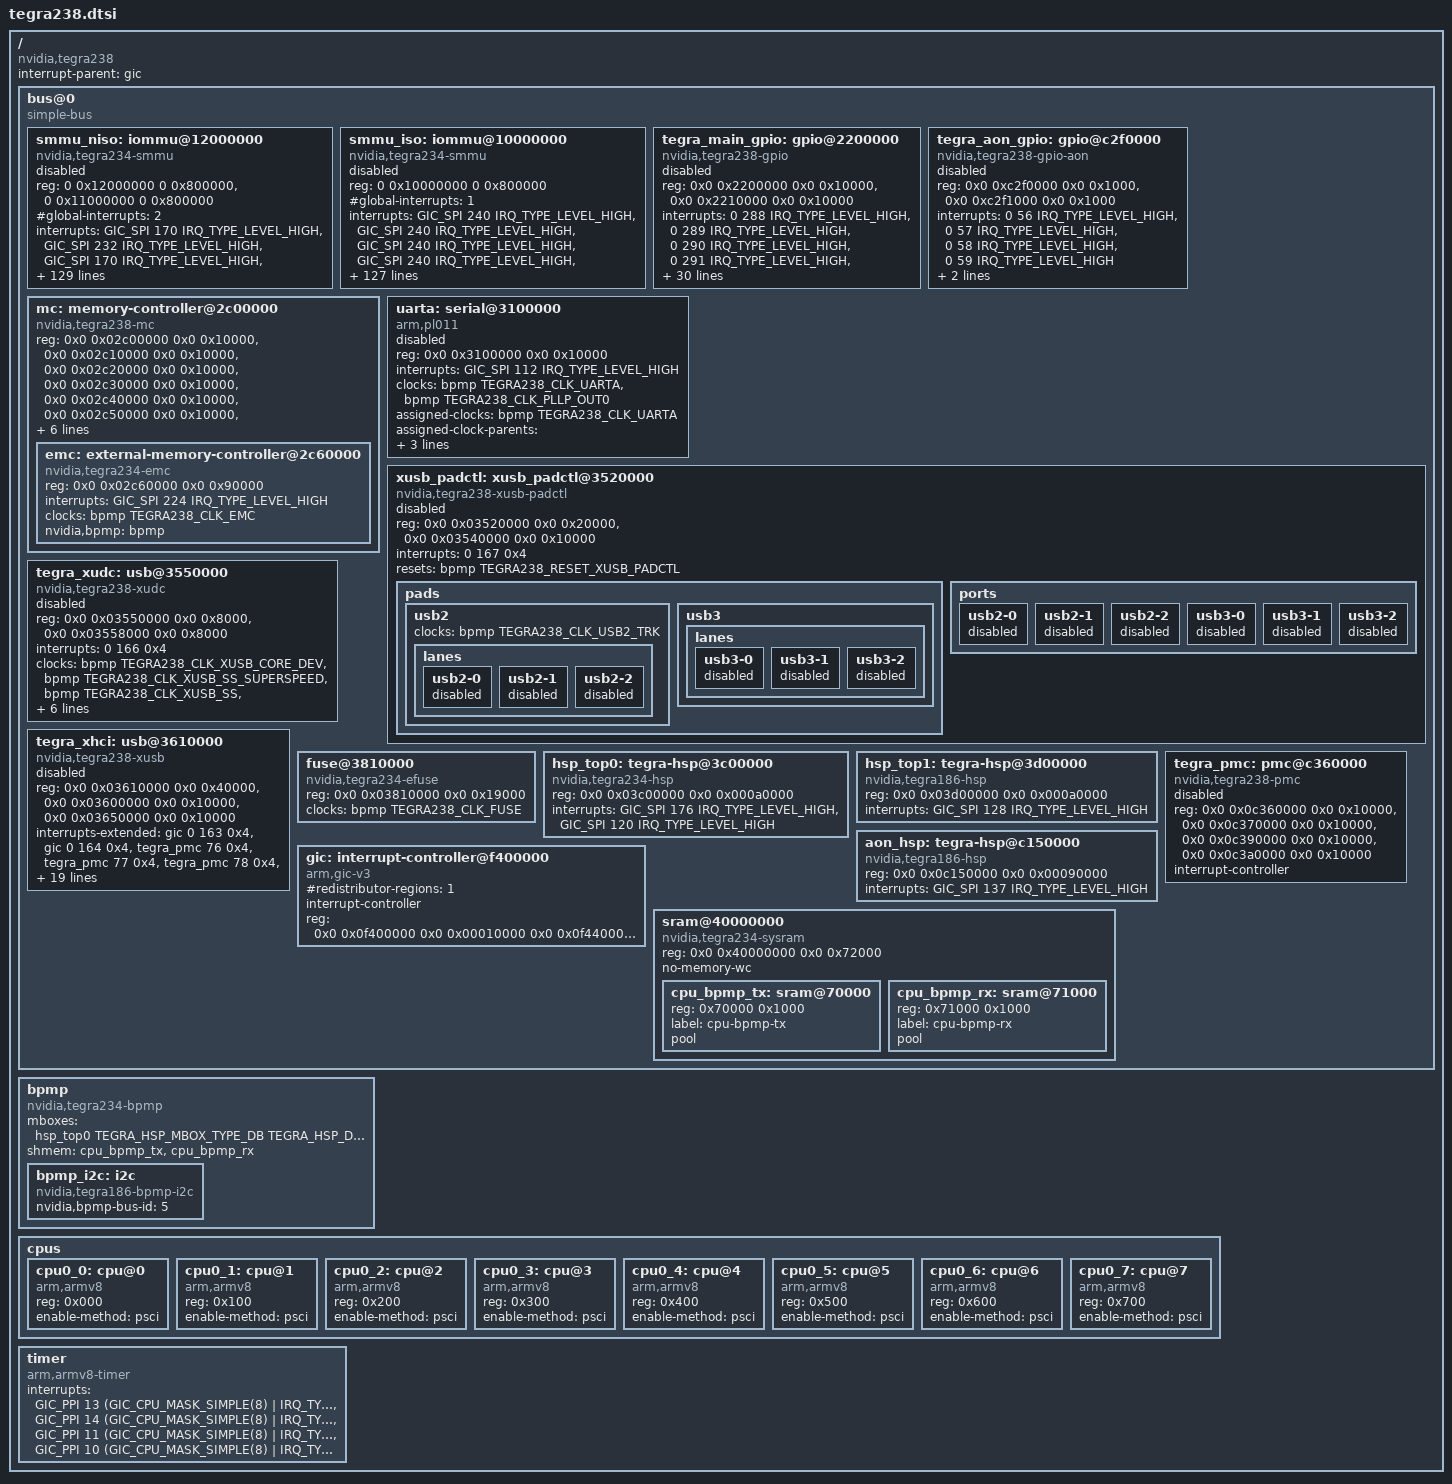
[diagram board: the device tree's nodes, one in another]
/* SPDX-License-Identifier: (GPL-2.0-only OR BSD-2-Clause) */

#include <dt-bindings/clock/nvidia,tegra238.h>
#include <dt-bindings/interrupt-controller/arm-gic.h>
#include <dt-bindings/mailbox/tegra186-hsp.h>
#include <dt-bindings/reset/nvidia,tegra238.h>
#include <dt-bindings/memory/nvidia,tegra238-mc.h>

/ {
	compatible = "nvidia,tegra238";
	interrupt-parent = <&gic>;
	#address-cells = <2>;
	#size-cells = <2>;

	bus@0 {
		compatible = "simple-bus";

		#address-cells = <2>;
		#size-cells = <2>;
		ranges = <0x0 0x0 0x0 0x0 0x0 0x80000000>;

		smmu_niso: iommu@12000000{
			compatible = "nvidia,tegra234-smmu", "nvidia,smmu-500";
			reg = <0 0x12000000 0 0x800000>,
			      <0 0x11000000 0 0x800000>;
			#global-interrupts = <2>;
			interrupts = <GIC_SPI 170 IRQ_TYPE_LEVEL_HIGH>,
				     <GIC_SPI 232 IRQ_TYPE_LEVEL_HIGH>,
				     <GIC_SPI 170 IRQ_TYPE_LEVEL_HIGH>,
				     <GIC_SPI 232 IRQ_TYPE_LEVEL_HIGH>,
				     <GIC_SPI 170 IRQ_TYPE_LEVEL_HIGH>,
				     <GIC_SPI 170 IRQ_TYPE_LEVEL_HIGH>,
				     <GIC_SPI 170 IRQ_TYPE_LEVEL_HIGH>,
				     <GIC_SPI 170 IRQ_TYPE_LEVEL_HIGH>,
				     <GIC_SPI 170 IRQ_TYPE_LEVEL_HIGH>,
				     <GIC_SPI 170 IRQ_TYPE_LEVEL_HIGH>,
				     <GIC_SPI 170 IRQ_TYPE_LEVEL_HIGH>,
				     <GIC_SPI 170 IRQ_TYPE_LEVEL_HIGH>,
				     <GIC_SPI 170 IRQ_TYPE_LEVEL_HIGH>,
				     <GIC_SPI 170 IRQ_TYPE_LEVEL_HIGH>,
				     <GIC_SPI 170 IRQ_TYPE_LEVEL_HIGH>,
				     <GIC_SPI 170 IRQ_TYPE_LEVEL_HIGH>,
				     <GIC_SPI 170 IRQ_TYPE_LEVEL_HIGH>,
				     <GIC_SPI 170 IRQ_TYPE_LEVEL_HIGH>,
				     <GIC_SPI 170 IRQ_TYPE_LEVEL_HIGH>,
				     <GIC_SPI 170 IRQ_TYPE_LEVEL_HIGH>,
				     <GIC_SPI 170 IRQ_TYPE_LEVEL_HIGH>,
				     <GIC_SPI 170 IRQ_TYPE_LEVEL_HIGH>,
				     <GIC_SPI 170 IRQ_TYPE_LEVEL_HIGH>,
				     <GIC_SPI 170 IRQ_TYPE_LEVEL_HIGH>,
				     <GIC_SPI 170 IRQ_TYPE_LEVEL_HIGH>,
				     <GIC_SPI 170 IRQ_TYPE_LEVEL_HIGH>,
				     <GIC_SPI 170 IRQ_TYPE_LEVEL_HIGH>,
				     <GIC_SPI 170 IRQ_TYPE_LEVEL_HIGH>,
				     <GIC_SPI 170 IRQ_TYPE_LEVEL_HIGH>,
				     <GIC_SPI 170 IRQ_TYPE_LEVEL_HIGH>,
				     <GIC_SPI 170 IRQ_TYPE_LEVEL_HIGH>,
				     <GIC_SPI 170 IRQ_TYPE_LEVEL_HIGH>,
				     <GIC_SPI 170 IRQ_TYPE_LEVEL_HIGH>,
				     <GIC_SPI 170 IRQ_TYPE_LEVEL_HIGH>,
				     <GIC_SPI 170 IRQ_TYPE_LEVEL_HIGH>,
				     <GIC_SPI 170 IRQ_TYPE_LEVEL_HIGH>,
				     <GIC_SPI 170 IRQ_TYPE_LEVEL_HIGH>,
				     <GIC_SPI 170 IRQ_TYPE_LEVEL_HIGH>,
				     <GIC_SPI 170 IRQ_TYPE_LEVEL_HIGH>,
				     <GIC_SPI 170 IRQ_TYPE_LEVEL_HIGH>,
				     <GIC_SPI 170 IRQ_TYPE_LEVEL_HIGH>,
				     <GIC_SPI 170 IRQ_TYPE_LEVEL_HIGH>,
				     <GIC_SPI 170 IRQ_TYPE_LEVEL_HIGH>,
				     <GIC_SPI 170 IRQ_TYPE_LEVEL_HIGH>,
				     <GIC_SPI 170 IRQ_TYPE_LEVEL_HIGH>,
				     <GIC_SPI 170 IRQ_TYPE_LEVEL_HIGH>,
				     <GIC_SPI 170 IRQ_TYPE_LEVEL_HIGH>,
				     <GIC_SPI 170 IRQ_TYPE_LEVEL_HIGH>,
				     <GIC_SPI 170 IRQ_TYPE_LEVEL_HIGH>,
				     <GIC_SPI 170 IRQ_TYPE_LEVEL_HIGH>,
				     <GIC_SPI 170 IRQ_TYPE_LEVEL_HIGH>,
				     <GIC_SPI 170 IRQ_TYPE_LEVEL_HIGH>,
				     <GIC_SPI 170 IRQ_TYPE_LEVEL_HIGH>,
				     <GIC_SPI 170 IRQ_TYPE_LEVEL_HIGH>,
				     <GIC_SPI 170 IRQ_TYPE_LEVEL_HIGH>,
				     <GIC_SPI 170 IRQ_TYPE_LEVEL_HIGH>,
				     <GIC_SPI 170 IRQ_TYPE_LEVEL_HIGH>,
				     <GIC_SPI 170 IRQ_TYPE_LEVEL_HIGH>,
				     <GIC_SPI 170 IRQ_TYPE_LEVEL_HIGH>,
				     <GIC_SPI 170 IRQ_TYPE_LEVEL_HIGH>,
				     <GIC_SPI 170 IRQ_TYPE_LEVEL_HIGH>,
				     <GIC_SPI 170 IRQ_TYPE_LEVEL_HIGH>,
				     <GIC_SPI 170 IRQ_TYPE_LEVEL_HIGH>,
				     <GIC_SPI 170 IRQ_TYPE_LEVEL_HIGH>,
				     <GIC_SPI 170 IRQ_TYPE_LEVEL_HIGH>,
				     <GIC_SPI 170 IRQ_TYPE_LEVEL_HIGH>,
				     <GIC_SPI 170 IRQ_TYPE_LEVEL_HIGH>,
				     <GIC_SPI 170 IRQ_TYPE_LEVEL_HIGH>,
				     <GIC_SPI 170 IRQ_TYPE_LEVEL_HIGH>,
				     <GIC_SPI 170 IRQ_TYPE_LEVEL_HIGH>,
				     <GIC_SPI 170 IRQ_TYPE_LEVEL_HIGH>,
				     <GIC_SPI 170 IRQ_TYPE_LEVEL_HIGH>,
				     <GIC_SPI 170 IRQ_TYPE_LEVEL_HIGH>,
				     <GIC_SPI 170 IRQ_TYPE_LEVEL_HIGH>,
				     <GIC_SPI 170 IRQ_TYPE_LEVEL_HIGH>,
				     <GIC_SPI 170 IRQ_TYPE_LEVEL_HIGH>,
				     <GIC_SPI 170 IRQ_TYPE_LEVEL_HIGH>,
				     <GIC_SPI 170 IRQ_TYPE_LEVEL_HIGH>,
				     <GIC_SPI 170 IRQ_TYPE_LEVEL_HIGH>,
				     <GIC_SPI 170 IRQ_TYPE_LEVEL_HIGH>,
				     <GIC_SPI 170 IRQ_TYPE_LEVEL_HIGH>,
				     <GIC_SPI 170 IRQ_TYPE_LEVEL_HIGH>,
				     <GIC_SPI 170 IRQ_TYPE_LEVEL_HIGH>,
				     <GIC_SPI 170 IRQ_TYPE_LEVEL_HIGH>,
				     <GIC_SPI 170 IRQ_TYPE_LEVEL_HIGH>,
				     <GIC_SPI 170 IRQ_TYPE_LEVEL_HIGH>,
				     <GIC_SPI 170 IRQ_TYPE_LEVEL_HIGH>,
				     <GIC_SPI 170 IRQ_TYPE_LEVEL_HIGH>,
				     <GIC_SPI 170 IRQ_TYPE_LEVEL_HIGH>,
				     <GIC_SPI 170 IRQ_TYPE_LEVEL_HIGH>,
				     <GIC_SPI 170 IRQ_TYPE_LEVEL_HIGH>,
				     <GIC_SPI 170 IRQ_TYPE_LEVEL_HIGH>,
				     <GIC_SPI 170 IRQ_TYPE_LEVEL_HIGH>,
				     <GIC_SPI 170 IRQ_TYPE_LEVEL_HIGH>,
				     <GIC_SPI 170 IRQ_TYPE_LEVEL_HIGH>,
				     <GIC_SPI 170 IRQ_TYPE_LEVEL_HIGH>,
				     <GIC_SPI 170 IRQ_TYPE_LEVEL_HIGH>,
				     <GIC_SPI 170 IRQ_TYPE_LEVEL_HIGH>,
				     <GIC_SPI 170 IRQ_TYPE_LEVEL_HIGH>,
				     <GIC_SPI 170 IRQ_TYPE_LEVEL_HIGH>,
				     <GIC_SPI 170 IRQ_TYPE_LEVEL_HIGH>,
				     <GIC_SPI 170 IRQ_TYPE_LEVEL_HIGH>,
				     <GIC_SPI 170 IRQ_TYPE_LEVEL_HIGH>,
				     <GIC_SPI 170 IRQ_TYPE_LEVEL_HIGH>,
				     <GIC_SPI 170 IRQ_TYPE_LEVEL_HIGH>,
				     <GIC_SPI 170 IRQ_TYPE_LEVEL_HIGH>,
				     <GIC_SPI 170 IRQ_TYPE_LEVEL_HIGH>,
				     <GIC_SPI 170 IRQ_TYPE_LEVEL_HIGH>,
				     <GIC_SPI 170 IRQ_TYPE_LEVEL_HIGH>,
				     <GIC_SPI 170 IRQ_TYPE_LEVEL_HIGH>,
				     <GIC_SPI 170 IRQ_TYPE_LEVEL_HIGH>,
				     <GIC_SPI 170 IRQ_TYPE_LEVEL_HIGH>,
				     <GIC_SPI 170 IRQ_TYPE_LEVEL_HIGH>,
				     <GIC_SPI 170 IRQ_TYPE_LEVEL_HIGH>,
				     <GIC_SPI 170 IRQ_TYPE_LEVEL_HIGH>,
				     <GIC_SPI 170 IRQ_TYPE_LEVEL_HIGH>,
				     <GIC_SPI 170 IRQ_TYPE_LEVEL_HIGH>,
				     <GIC_SPI 170 IRQ_TYPE_LEVEL_HIGH>,
				     <GIC_SPI 170 IRQ_TYPE_LEVEL_HIGH>,
				     <GIC_SPI 170 IRQ_TYPE_LEVEL_HIGH>,
				     <GIC_SPI 170 IRQ_TYPE_LEVEL_HIGH>,
				     <GIC_SPI 170 IRQ_TYPE_LEVEL_HIGH>,
				     <GIC_SPI 170 IRQ_TYPE_LEVEL_HIGH>,
				     <GIC_SPI 170 IRQ_TYPE_LEVEL_HIGH>,
				     <GIC_SPI 170 IRQ_TYPE_LEVEL_HIGH>,
				     <GIC_SPI 170 IRQ_TYPE_LEVEL_HIGH>,
				     <GIC_SPI 170 IRQ_TYPE_LEVEL_HIGH>,
				     <GIC_SPI 170 IRQ_TYPE_LEVEL_HIGH>,
				     <GIC_SPI 170 IRQ_TYPE_LEVEL_HIGH>,
				     <GIC_SPI 170 IRQ_TYPE_LEVEL_HIGH>;
			stream-match-mask = <0x7F80>;
			nvidia,memory-controller = <&mc>;
			#iommu-cells = <1>;
			status = "disabled";
		};

		smmu_iso: iommu@10000000{
			compatible = "nvidia,tegra234-smmu", "nvidia,smmu-500";
			reg = <0 0x10000000 0 0x800000>;
			#global-interrupts = <1>;
			interrupts = <GIC_SPI 240 IRQ_TYPE_LEVEL_HIGH>,
				     <GIC_SPI 240 IRQ_TYPE_LEVEL_HIGH>,
				     <GIC_SPI 240 IRQ_TYPE_LEVEL_HIGH>,
				     <GIC_SPI 240 IRQ_TYPE_LEVEL_HIGH>,
				     <GIC_SPI 240 IRQ_TYPE_LEVEL_HIGH>,
				     <GIC_SPI 240 IRQ_TYPE_LEVEL_HIGH>,
				     <GIC_SPI 240 IRQ_TYPE_LEVEL_HIGH>,
				     <GIC_SPI 240 IRQ_TYPE_LEVEL_HIGH>,
				     <GIC_SPI 240 IRQ_TYPE_LEVEL_HIGH>,
				     <GIC_SPI 240 IRQ_TYPE_LEVEL_HIGH>,
				     <GIC_SPI 240 IRQ_TYPE_LEVEL_HIGH>,
				     <GIC_SPI 240 IRQ_TYPE_LEVEL_HIGH>,
				     <GIC_SPI 240 IRQ_TYPE_LEVEL_HIGH>,
				     <GIC_SPI 240 IRQ_TYPE_LEVEL_HIGH>,
				     <GIC_SPI 240 IRQ_TYPE_LEVEL_HIGH>,
				     <GIC_SPI 240 IRQ_TYPE_LEVEL_HIGH>,
				     <GIC_SPI 240 IRQ_TYPE_LEVEL_HIGH>,
				     <GIC_SPI 240 IRQ_TYPE_LEVEL_HIGH>,
				     <GIC_SPI 240 IRQ_TYPE_LEVEL_HIGH>,
				     <GIC_SPI 240 IRQ_TYPE_LEVEL_HIGH>,
				     <GIC_SPI 240 IRQ_TYPE_LEVEL_HIGH>,
				     <GIC_SPI 240 IRQ_TYPE_LEVEL_HIGH>,
				     <GIC_SPI 240 IRQ_TYPE_LEVEL_HIGH>,
				     <GIC_SPI 240 IRQ_TYPE_LEVEL_HIGH>,
				     <GIC_SPI 240 IRQ_TYPE_LEVEL_HIGH>,
				     <GIC_SPI 240 IRQ_TYPE_LEVEL_HIGH>,
				     <GIC_SPI 240 IRQ_TYPE_LEVEL_HIGH>,
				     <GIC_SPI 240 IRQ_TYPE_LEVEL_HIGH>,
				     <GIC_SPI 240 IRQ_TYPE_LEVEL_HIGH>,
				     <GIC_SPI 240 IRQ_TYPE_LEVEL_HIGH>,
				     <GIC_SPI 240 IRQ_TYPE_LEVEL_HIGH>,
				     <GIC_SPI 240 IRQ_TYPE_LEVEL_HIGH>,
				     <GIC_SPI 240 IRQ_TYPE_LEVEL_HIGH>,
				     <GIC_SPI 240 IRQ_TYPE_LEVEL_HIGH>,
				     <GIC_SPI 240 IRQ_TYPE_LEVEL_HIGH>,
				     <GIC_SPI 240 IRQ_TYPE_LEVEL_HIGH>,
				     <GIC_SPI 240 IRQ_TYPE_LEVEL_HIGH>,
				     <GIC_SPI 240 IRQ_TYPE_LEVEL_HIGH>,
				     <GIC_SPI 240 IRQ_TYPE_LEVEL_HIGH>,
				     <GIC_SPI 240 IRQ_TYPE_LEVEL_HIGH>,
				     <GIC_SPI 240 IRQ_TYPE_LEVEL_HIGH>,
				     <GIC_SPI 240 IRQ_TYPE_LEVEL_HIGH>,
				     <GIC_SPI 240 IRQ_TYPE_LEVEL_HIGH>,
				     <GIC_SPI 240 IRQ_TYPE_LEVEL_HIGH>,
				     <GIC_SPI 240 IRQ_TYPE_LEVEL_HIGH>,
				     <GIC_SPI 240 IRQ_TYPE_LEVEL_HIGH>,
				     <GIC_SPI 240 IRQ_TYPE_LEVEL_HIGH>,
				     <GIC_SPI 240 IRQ_TYPE_LEVEL_HIGH>,
				     <GIC_SPI 240 IRQ_TYPE_LEVEL_HIGH>,
				     <GIC_SPI 240 IRQ_TYPE_LEVEL_HIGH>,
				     <GIC_SPI 240 IRQ_TYPE_LEVEL_HIGH>,
				     <GIC_SPI 240 IRQ_TYPE_LEVEL_HIGH>,
				     <GIC_SPI 240 IRQ_TYPE_LEVEL_HIGH>,
				     <GIC_SPI 240 IRQ_TYPE_LEVEL_HIGH>,
				     <GIC_SPI 240 IRQ_TYPE_LEVEL_HIGH>,
				     <GIC_SPI 240 IRQ_TYPE_LEVEL_HIGH>,
				     <GIC_SPI 240 IRQ_TYPE_LEVEL_HIGH>,
				     <GIC_SPI 240 IRQ_TYPE_LEVEL_HIGH>,
				     <GIC_SPI 240 IRQ_TYPE_LEVEL_HIGH>,
				     <GIC_SPI 240 IRQ_TYPE_LEVEL_HIGH>,
				     <GIC_SPI 240 IRQ_TYPE_LEVEL_HIGH>,
				     <GIC_SPI 240 IRQ_TYPE_LEVEL_HIGH>,
				     <GIC_SPI 240 IRQ_TYPE_LEVEL_HIGH>,
				     <GIC_SPI 240 IRQ_TYPE_LEVEL_HIGH>,
				     <GIC_SPI 240 IRQ_TYPE_LEVEL_HIGH>,
				     <GIC_SPI 240 IRQ_TYPE_LEVEL_HIGH>,
				     <GIC_SPI 240 IRQ_TYPE_LEVEL_HIGH>,
				     <GIC_SPI 240 IRQ_TYPE_LEVEL_HIGH>,
				     <GIC_SPI 240 IRQ_TYPE_LEVEL_HIGH>,
				     <GIC_SPI 240 IRQ_TYPE_LEVEL_HIGH>,
				     <GIC_SPI 240 IRQ_TYPE_LEVEL_HIGH>,
				     <GIC_SPI 240 IRQ_TYPE_LEVEL_HIGH>,
				     <GIC_SPI 240 IRQ_TYPE_LEVEL_HIGH>,
				     <GIC_SPI 240 IRQ_TYPE_LEVEL_HIGH>,
				     <GIC_SPI 240 IRQ_TYPE_LEVEL_HIGH>,
				     <GIC_SPI 240 IRQ_TYPE_LEVEL_HIGH>,
				     <GIC_SPI 240 IRQ_TYPE_LEVEL_HIGH>,
				     <GIC_SPI 240 IRQ_TYPE_LEVEL_HIGH>,
				     <GIC_SPI 240 IRQ_TYPE_LEVEL_HIGH>,
				     <GIC_SPI 240 IRQ_TYPE_LEVEL_HIGH>,
				     <GIC_SPI 240 IRQ_TYPE_LEVEL_HIGH>,
				     <GIC_SPI 240 IRQ_TYPE_LEVEL_HIGH>,
				     <GIC_SPI 240 IRQ_TYPE_LEVEL_HIGH>,
				     <GIC_SPI 240 IRQ_TYPE_LEVEL_HIGH>,
				     <GIC_SPI 240 IRQ_TYPE_LEVEL_HIGH>,
				     <GIC_SPI 240 IRQ_TYPE_LEVEL_HIGH>,
				     <GIC_SPI 240 IRQ_TYPE_LEVEL_HIGH>,
				     <GIC_SPI 240 IRQ_TYPE_LEVEL_HIGH>,
				     <GIC_SPI 240 IRQ_TYPE_LEVEL_HIGH>,
				     <GIC_SPI 240 IRQ_TYPE_LEVEL_HIGH>,
				     <GIC_SPI 240 IRQ_TYPE_LEVEL_HIGH>,
				     <GIC_SPI 240 IRQ_TYPE_LEVEL_HIGH>,
				     <GIC_SPI 240 IRQ_TYPE_LEVEL_HIGH>,
				     <GIC_SPI 240 IRQ_TYPE_LEVEL_HIGH>,
				     <GIC_SPI 240 IRQ_TYPE_LEVEL_HIGH>,
				     <GIC_SPI 240 IRQ_TYPE_LEVEL_HIGH>,
				     <GIC_SPI 240 IRQ_TYPE_LEVEL_HIGH>,
				     <GIC_SPI 240 IRQ_TYPE_LEVEL_HIGH>,
				     <GIC_SPI 240 IRQ_TYPE_LEVEL_HIGH>,
				     <GIC_SPI 240 IRQ_TYPE_LEVEL_HIGH>,
				     <GIC_SPI 240 IRQ_TYPE_LEVEL_HIGH>,
				     <GIC_SPI 240 IRQ_TYPE_LEVEL_HIGH>,
				     <GIC_SPI 240 IRQ_TYPE_LEVEL_HIGH>,
				     <GIC_SPI 240 IRQ_TYPE_LEVEL_HIGH>,
				     <GIC_SPI 240 IRQ_TYPE_LEVEL_HIGH>,
				     <GIC_SPI 240 IRQ_TYPE_LEVEL_HIGH>,
				     <GIC_SPI 240 IRQ_TYPE_LEVEL_HIGH>,
				     <GIC_SPI 240 IRQ_TYPE_LEVEL_HIGH>,
				     <GIC_SPI 240 IRQ_TYPE_LEVEL_HIGH>,
				     <GIC_SPI 240 IRQ_TYPE_LEVEL_HIGH>,
				     <GIC_SPI 240 IRQ_TYPE_LEVEL_HIGH>,
				     <GIC_SPI 240 IRQ_TYPE_LEVEL_HIGH>,
				     <GIC_SPI 240 IRQ_TYPE_LEVEL_HIGH>,
				     <GIC_SPI 240 IRQ_TYPE_LEVEL_HIGH>,
				     <GIC_SPI 240 IRQ_TYPE_LEVEL_HIGH>,
				     <GIC_SPI 240 IRQ_TYPE_LEVEL_HIGH>,
				     <GIC_SPI 240 IRQ_TYPE_LEVEL_HIGH>,
				     <GIC_SPI 240 IRQ_TYPE_LEVEL_HIGH>,
				     <GIC_SPI 240 IRQ_TYPE_LEVEL_HIGH>,
				     <GIC_SPI 240 IRQ_TYPE_LEVEL_HIGH>,
				     <GIC_SPI 240 IRQ_TYPE_LEVEL_HIGH>,
				     <GIC_SPI 240 IRQ_TYPE_LEVEL_HIGH>,
				     <GIC_SPI 240 IRQ_TYPE_LEVEL_HIGH>,
				     <GIC_SPI 240 IRQ_TYPE_LEVEL_HIGH>,
				     <GIC_SPI 240 IRQ_TYPE_LEVEL_HIGH>,
				     <GIC_SPI 240 IRQ_TYPE_LEVEL_HIGH>,
				     <GIC_SPI 240 IRQ_TYPE_LEVEL_HIGH>,
				     <GIC_SPI 240 IRQ_TYPE_LEVEL_HIGH>,
				     <GIC_SPI 240 IRQ_TYPE_LEVEL_HIGH>;
			stream-match-mask = <0x7F80>;
			nvidia,memory-controller = <&mc>;
			#iommu-cells = <1>;
			status = "disabled";
		};

		tegra_main_gpio: gpio@2200000 {
			compatible = "nvidia,tegra238-gpio";
			reg-names = "security", "gpio";
			reg =
				<0x0 0x2200000 0x0 0x10000>,
				<0x0 0x2210000 0x0 0x10000>;
			interrupts =
				<0 288 IRQ_TYPE_LEVEL_HIGH>,
				<0 289 IRQ_TYPE_LEVEL_HIGH>,
				<0 290 IRQ_TYPE_LEVEL_HIGH>,
				<0 291 IRQ_TYPE_LEVEL_HIGH>,
				<0 292 IRQ_TYPE_LEVEL_HIGH>,
				<0 293 IRQ_TYPE_LEVEL_HIGH>,
				<0 294 IRQ_TYPE_LEVEL_HIGH>,
				<0 295 IRQ_TYPE_LEVEL_HIGH>,
				<0 296 IRQ_TYPE_LEVEL_HIGH>,
				<0 297 IRQ_TYPE_LEVEL_HIGH>,
				<0 298 IRQ_TYPE_LEVEL_HIGH>,
				<0 299 IRQ_TYPE_LEVEL_HIGH>,
				<0 300 IRQ_TYPE_LEVEL_HIGH>,
				<0 301 IRQ_TYPE_LEVEL_HIGH>,
				<0 302 IRQ_TYPE_LEVEL_HIGH>,
				<0 303 IRQ_TYPE_LEVEL_HIGH>,
				<0 304 IRQ_TYPE_LEVEL_HIGH>,
				<0 305 IRQ_TYPE_LEVEL_HIGH>,
				<0 306 IRQ_TYPE_LEVEL_HIGH>,
				<0 307 IRQ_TYPE_LEVEL_HIGH>,
				<0 308 IRQ_TYPE_LEVEL_HIGH>,
				<0 309 IRQ_TYPE_LEVEL_HIGH>,
				<0 310 IRQ_TYPE_LEVEL_HIGH>,
				<0 311 IRQ_TYPE_LEVEL_HIGH>,
				<0 312 IRQ_TYPE_LEVEL_HIGH>,
				<0 313 IRQ_TYPE_LEVEL_HIGH>,
				<0 314 IRQ_TYPE_LEVEL_HIGH>,
				<0 315 IRQ_TYPE_LEVEL_HIGH>,
				<0 316 IRQ_TYPE_LEVEL_HIGH>,
				<0 317 IRQ_TYPE_LEVEL_HIGH>,
				<0 318 IRQ_TYPE_LEVEL_HIGH>,
				<0 319 IRQ_TYPE_LEVEL_HIGH>;
			gpio-controller;
			#gpio-cells = <2>;
			interrupt-controller;
			#interrupt-cells = <2>;
			status = "disabled";
		};

		tegra_aon_gpio: gpio@c2f0000 {
			compatible = "nvidia,tegra238-gpio-aon";
			reg-names = "security", "gpio";
			reg = 	<0x0 0xc2f0000 0x0 0x1000>,
				<0x0 0xc2f1000 0x0 0x1000>;
			interrupts =
				<0 56 IRQ_TYPE_LEVEL_HIGH>,
				<0 57 IRQ_TYPE_LEVEL_HIGH>,
				<0 58 IRQ_TYPE_LEVEL_HIGH>,
				<0 59 IRQ_TYPE_LEVEL_HIGH>;
			gpio-controller;
			#gpio-cells = <2>;
			interrupt-controller;
			#interrupt-cells = <2>;
			status = "disabled";
		};

		mc: memory-controller@2c00000 {
			compatible = "nvidia,tegra238-mc";
			reg = <0x0 0x02c00000 0x0 0x10000>,   /* MC-SID */
			      <0x0 0x02c10000 0x0 0x10000>,   /* MC Broadcast*/
			      <0x0 0x02c20000 0x0 0x10000>,   /* MC0 */
			      <0x0 0x02c30000 0x0 0x10000>,   /* MC1 */
			      <0x0 0x02c40000 0x0 0x10000>,   /* MC2 */
			      <0x0 0x02c50000 0x0 0x10000>,   /* MC3 */
			      <0x0 0x02b80000 0x0 0x10000>,   /* MC4 */
			      <0x0 0x02b90000 0x0 0x10000>,   /* MC5 */
			      <0x0 0x02ba0000 0x0 0x10000>,   /* MC6 */
			      <0x0 0x02bb0000 0x0 0x10000>;   /* MC7 */
			reg-names = "sid", "broadcast", "ch0", "ch1", "ch2", "ch3",
				    "ch4", "ch5", "ch6", "ch7";
			interrupts = <GIC_SPI 223 IRQ_TYPE_LEVEL_HIGH>;
			#interconnect-cells = <1>;
			status = "okay";

			#address-cells = <2>;
			#size-cells = <2>;

			ranges = <0x0 0x02b80000 0x0 0x02b80000 0x0 0x040000>,
				 <0x0 0x02c00000 0x0 0x02c00000 0x0 0x100000>;

			/*
			 * Bit 39 of addresses passing through the memory
			 * controller selects the XBAR format used when memory
			 * is accessed. This is used to transparently access
			 * memory in the XBAR format used by the discrete GPU
			 * (bit 39 set) or Tegra (bit 39 clear).
			 *
			 * As a consequence, the operating system must ensure
			 * that bit 39 is never used implicitly, for example
			 * via an I/O virtual address mapping of an IOMMU. If
			 * devices require access to the XBAR switch, their
			 * drivers must set this bit explicitly.
			 *
			 * Limit the DMA range for memory clients to [38:0].
			 */
			dma-ranges = <0x0 0x0 0x0 0x0 0x80 0x0>;

			emc: external-memory-controller@2c60000 {
				compatible = "nvidia,tegra234-emc";
				reg = <0x0 0x02c60000 0x0 0x90000>;
				interrupts = <GIC_SPI 224 IRQ_TYPE_LEVEL_HIGH>;
				clocks = <&bpmp TEGRA238_CLK_EMC>;
				clock-names = "emc";
				status = "okay";
				#interconnect-cells = <0>;
				nvidia,bpmp = <&bpmp>;
			};
		};

		uarta: serial@3100000 {
			compatible = "arm,pl011", "arm,primecell";
			reg = <0x0 0x3100000 0x0 0x10000>;
			interrupts = <GIC_SPI 112 IRQ_TYPE_LEVEL_HIGH>;
			clocks = <&bpmp TEGRA238_CLK_UARTA>,
				 <&bpmp TEGRA238_CLK_PLLP_OUT0>;
			clock-names = "uartclk", "apb_pclk";
			assigned-clocks = <&bpmp TEGRA238_CLK_UARTA>;
			assigned-clock-parents = <&bpmp TEGRA238_CLK_PLLP_OUT0>;
			resets = <&bpmp TEGRA238_RESET_UARTA>;
			arm,primecell-periphid = <0x00051011>;
			status = "disabled";
		};

		xusb_padctl: xusb_padctl@3520000 {
			compatible = "nvidia,tegra238-xusb-padctl";
			reg = <0x0 0x03520000 0x0 0x20000>,
			     <0x0 0x03540000 0x0 0x10000>;
			reg-names = "padctl", "ao";
			interrupts = <0 167 0x4>;
			resets = <&bpmp TEGRA238_RESET_XUSB_PADCTL>;
			reset-names = "padctl";
			status = "disabled";

			pads {
				usb2 {
					clocks = <&bpmp TEGRA238_CLK_USB2_TRK>;
					clock-names = "trk";

					lanes {
						usb2-0 {
							status = "disabled";
							#phy-cells = <0>;
						};
						usb2-1 {
							status = "disabled";
							#phy-cells = <0>;
						};
						usb2-2 {
							status = "disabled";
							#phy-cells = <0>;
						};
					};
				};
				usb3 {
					lanes {
						usb3-0 {
							status = "disabled";
							#phy-cells = <0>;
						};
						usb3-1 {
							status = "disabled";
							#phy-cells = <0>;
						};
						usb3-2 {
							status = "disabled";
							#phy-cells = <0>;
						};
					};
				};
			};

			ports {
				usb2-0 {
					status = "disabled";
				};
				usb2-1 {
					status = "disabled";
				};
				usb2-2 {
					status = "disabled";
				};
				usb3-0 {
					status = "disabled";
				};
				usb3-1 {
					status = "disabled";
				};
				usb3-2 {
					status = "disabled";
				};
			};
		};

		tegra_xudc: usb@3550000 {
			compatible = "nvidia,tegra238-xudc";
			reg = <0x0 0x03550000 0x0 0x8000>,
				<0x0 0x03558000 0x0 0x8000>;
			reg-names = "base", "fpci";
			interrupts = <0 166 0x4>;
			clocks = <&bpmp TEGRA238_CLK_XUSB_CORE_DEV>,
				<&bpmp TEGRA238_CLK_XUSB_SS_SUPERSPEED>,
				<&bpmp TEGRA238_CLK_XUSB_SS>,
				<&bpmp TEGRA238_CLK_XUSB_FS>;
			clock-names = "dev", "ss", "ss_src", "fs_src";
			resets = <&bpmp TEGRA238_RESET_XUSB_DEV>,
				 <&bpmp TEGRA238_RESET_XUSB_SS>;
			reset-names = "xusb_dev",
				      "xusb_ss";

			nvidia,xusb-padctl = <&xusb_padctl>;

			iommus = <&smmu_niso TEGRA238_SID_XUSB_DEV>;
			dma-coherent;

			status = "disabled";
		};

		tegra_xhci: usb@3610000 {
			compatible = "nvidia,tegra238-xusb";
			reg = <0x0 0x03610000 0x0 0x40000>,
			      <0x0 0x03600000 0x0 0x10000>,
			      <0x0 0x03650000 0x0 0x10000>;
			reg-names = "hcd", "fpci", "bar2";
			interrupts-extended = <&gic 0 163 0x4>,
					      <&gic 0 164 0x4>,
					      <&tegra_pmc 76 0x4>,
					      <&tegra_pmc 77 0x4>,
					      <&tegra_pmc 78 0x4>,
					      <&tegra_pmc 79 0x4>,
					      <&tegra_pmc 80 0x4>,
					      <&tegra_pmc 81 0x4>;
			clocks = <&bpmp TEGRA238_CLK_XUSB_CORE_HOST>,
				<&bpmp TEGRA238_CLK_XUSB_FALCON>,
				<&bpmp TEGRA238_CLK_XUSB_SS_SUPERSPEED>,
				<&bpmp TEGRA238_CLK_XUSB_SS>,
				<&bpmp TEGRA238_CLK_XUSB_CORE_MUX>,
				<&bpmp TEGRA238_CLK_XUSB_FS>,
				<&bpmp TEGRA238_CLK_UTMIP_PLL>,
				<&bpmp TEGRA238_CLK_CLK_M>,
				<&bpmp TEGRA238_CLK_PLLE>;
			clock-names = "xusb_host", "xusb_falcon_src", "xusb_ss",
				"xusb_ss_src", "xusb_hs_src", "xusb_fs_src",
				"pll_u_480m", "clk_m", "pll_e";
			resets = <&bpmp TEGRA238_RESET_XUSB_HOST>,
				 <&bpmp TEGRA238_RESET_XUSB_SS>;
			reset-names = "xusb_host",
				      "xusb_ss";

			nvidia,xusb-padctl = <&xusb_padctl>;

			interconnects = <&mc TEGRA238_MEMORY_CLIENT_XUSB_HOSTR &emc>,
					<&mc TEGRA238_MEMORY_CLIENT_XUSB_HOSTW &emc>;
			interconnect-names = "dma-mem", "write";

			iommus = <&smmu_niso TEGRA238_SID_XUSB_HOST>;
			dma-coherent;

			status = "disabled";
		};

		fuse@3810000 {
			compatible = "nvidia,tegra234-efuse";
			reg = <0x0 0x03810000 0x0 0x19000>;
			clocks = <&bpmp TEGRA238_CLK_FUSE>;
			clock-names = "fuse";
		};

		hsp_top0: tegra-hsp@3c00000 {
			compatible = "nvidia,tegra234-hsp", "nvidia,tegra194-hsp";
			reg = <0x0 0x03c00000 0x0 0x000a0000>;
			interrupts = <GIC_SPI 176 IRQ_TYPE_LEVEL_HIGH>,
				     <GIC_SPI 120 IRQ_TYPE_LEVEL_HIGH>;
			interrupt-names = "doorbell", "shared0";
			#mbox-cells = <2>;
		};

		hsp_top1: tegra-hsp@3d00000 {
			compatible = "nvidia,tegra186-hsp";
			reg = <0x0 0x03d00000 0x0 0x000a0000>;
			interrupts = <GIC_SPI 128 IRQ_TYPE_LEVEL_HIGH>;
			interrupt-names = "shared0";
			#mbox-cells = <2>;
		};

		aon_hsp: tegra-hsp@c150000 {
			compatible = "nvidia,tegra186-hsp";
			reg = <0x0 0x0c150000 0x0 0x00090000>;
			interrupts = <GIC_SPI 137 IRQ_TYPE_LEVEL_HIGH>;
			interrupt-names = "shared1";
		};

		tegra_pmc: pmc@c360000 {
			compatible = "nvidia,tegra238-pmc";
			reg = <0x0 0x0c360000 0x0 0x10000>,
			      <0x0 0x0c370000 0x0 0x10000>,
			      <0x0 0x0c390000 0x0 0x10000>,
			      <0x0 0x0c3a0000 0x0 0x10000>;
			reg-names = "pmc", "wake", "scratch", "misc";

			#interrupt-cells = <2>;
			interrupt-controller;
			#padcontroller-cells = <1>;
			status = "disabled";
		};

		gic: interrupt-controller@f400000 {
			compatible = "arm,gic-v3";
			#interrupt-cells = <3>;
			#address-cells = <0>;
			#redistributor-regions = <1>;
			interrupt-controller;
			reg = <0x0 0x0f400000 0x0 0x00010000	/* GICD */
			       0x0 0x0f440000 0x0 0x00200000>;	/* GICR CPU 0-15 */
		};

		sram@40000000 {
			compatible = "nvidia,tegra234-sysram", "mmio-sram";
			reg = <0x0 0x40000000 0x0 0x72000>;
			ranges = <0x0 0x0 0x40000000 0x72000>;
			#address-cells = <1>;
			#size-cells = <1>;
			no-memory-wc;

			cpu_bpmp_tx: sram@70000 {
				reg = <0x70000 0x1000>;
				label = "cpu-bpmp-tx";
				pool;
			};

			cpu_bpmp_rx: sram@71000 {
				reg = <0x71000 0x1000>;
				label = "cpu-bpmp-rx";
				pool;
			};
		};
	};

	bpmp: bpmp {
		compatible = "nvidia,tegra234-bpmp", "nvidia,tegra186-bpmp";
		mboxes = <&hsp_top0 TEGRA_HSP_MBOX_TYPE_DB TEGRA_HSP_DB_MASTER_BPMP>;
		shmem = <&cpu_bpmp_tx &cpu_bpmp_rx>;
		#clock-cells = <1>;
		#reset-cells = <1>;
		#power-domain-cells = <1>;

		bpmp_i2c: i2c {
			compatible = "nvidia,tegra186-bpmp-i2c";
			nvidia,bpmp-bus-id = <5>;
			#address-cells = <1>;
			#size-cells = <0>;
		};
	};

	cpus {
		#address-cells = <1>;
		#size-cells = <0>;

		cpu0_0: cpu@0 {
			compatible = "arm,armv8";
			device_type = "cpu";
			reg = <0x000>;

			enable-method = "psci";
		};

		cpu0_1: cpu@1 {
			compatible = "arm,armv8";
			device_type = "cpu";
			reg = <0x100>;

			enable-method = "psci";
		};

		cpu0_2: cpu@2 {
			compatible = "arm,armv8";
			device_type = "cpu";
			reg = <0x200>;

			enable-method = "psci";
		};

		cpu0_3: cpu@3 {
			compatible = "arm,armv8";
			device_type = "cpu";
			reg = <0x300>;

			enable-method = "psci";
		};

		cpu0_4: cpu@4 {
			compatible = "arm,armv8";
			device_type = "cpu";
			reg = <0x400>;

			enable-method = "psci";
		};

		cpu0_5: cpu@5 {
			compatible = "arm,armv8";
			device_type = "cpu";
			reg = <0x500>;

			enable-method = "psci";
		};

		cpu0_6: cpu@6 {
			compatible = "arm,armv8";
			device_type = "cpu";
			reg = <0x600>;

			enable-method = "psci";
		};

		cpu0_7: cpu@7 {
			compatible = "arm,armv8";
			device_type = "cpu";
			reg = <0x700>;

			enable-method = "psci";
		};
	};

	timer {
		compatible = "arm,armv8-timer";
		interrupts = <GIC_PPI 13 (GIC_CPU_MASK_SIMPLE(8) | IRQ_TYPE_LEVEL_LOW)>,
			     <GIC_PPI 14 (GIC_CPU_MASK_SIMPLE(8) | IRQ_TYPE_LEVEL_LOW)>,
			     <GIC_PPI 11 (GIC_CPU_MASK_SIMPLE(8) | IRQ_TYPE_LEVEL_LOW)>,
			     <GIC_PPI 10 (GIC_CPU_MASK_SIMPLE(8) | IRQ_TYPE_LEVEL_LOW)>;
	};
};
